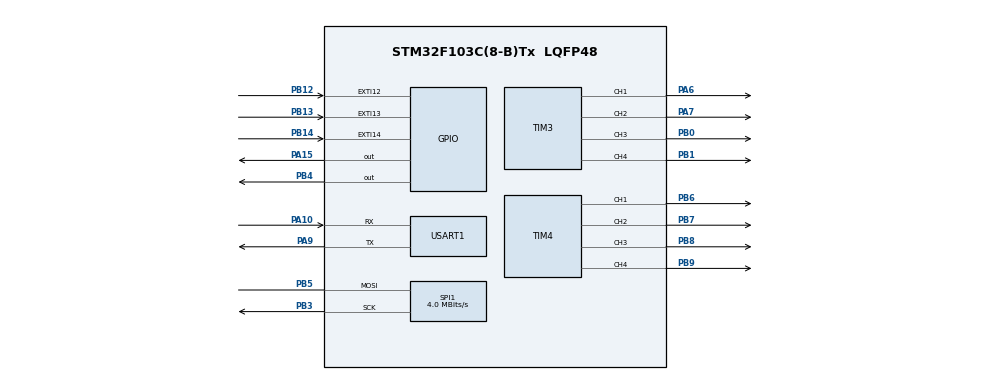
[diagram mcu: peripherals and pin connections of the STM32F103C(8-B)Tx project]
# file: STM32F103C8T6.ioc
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FREERTOS.Tasks01=defaultTask,24,128,StartDefaultTask,Default,NULL,Dynamic,NULL,NULL
Mcu.Family=STM32F1
Mcu.Name=STM32F103C(8-B)Tx
Mcu.Package=LQFP48
NVIC.PriorityGroup=NVIC_PRIORITYGROUP_4
PA10.Mode=Asynchronous
PA10.Signal=USART1_RX
PA13.Mode=Serial_Wire
PA13.Signal=SYS_JTMS-SWDIO
PA14.Mode=Serial_Wire
PA14.Signal=SYS_JTCK-SWCLK
PA15.Signal=GPIO_Output
PA6.Signal=S_TIM3_CH1
PA7.Signal=S_TIM3_CH2
PA9.Mode=Asynchronous
PA9.Signal=USART1_TX
PB0.Signal=S_TIM3_CH3
PB1.Signal=S_TIM3_CH4
PB12.GPIO_ModeDefaultEXTI=GPIO_MODE_IT_FALLING
PB12.GPIO_PuPd=GPIO_PULLUP
PB12.Signal=GPXTI12
PB13.GPIO_ModeDefaultEXTI=GPIO_MODE_IT_FALLING
PB13.GPIO_PuPd=GPIO_PULLUP
PB13.Signal=GPXTI13
PB14.GPIO_ModeDefaultEXTI=GPIO_MODE_IT_FALLING
PB14.GPIO_PuPd=GPIO_PULLUP
PB14.Signal=GPXTI14
PB3.Mode=Simplex_Bidirectional_Master
PB3.Signal=SPI1_SCK
PB4.Signal=GPIO_Output
PB5.Mode=Simplex_Bidirectional_Master
PB5.Signal=SPI1_MOSI
PB6.Signal=S_TIM4_CH1
PB7.Signal=S_TIM4_CH2
PB8.Signal=S_TIM4_CH3
PB9.Signal=S_TIM4_CH4
ProjectManager.HeapSize=0x200
ProjectManager.StackSize=0x400
ProjectManager.TargetToolchain=SW4STM32
RCC.APB1Freq_Value=8000000
RCC.APB2Freq_Value=8000000
SH.S_TIM3_CH1.0=TIM3_CH1,PWM Generation1 CH1
SH.S_TIM3_CH2.0=TIM3_CH2,PWM Generation2 CH2
SH.S_TIM3_CH3.0=TIM3_CH3,PWM Generation3 CH3
SH.S_TIM3_CH4.0=TIM3_CH4,PWM Generation4 CH4
SH.S_TIM4_CH1.0=TIM4_CH1,PWM Generation1 CH1
SH.S_TIM4_CH2.0=TIM4_CH2,PWM Generation2 CH2
SH.S_TIM4_CH3.0=TIM4_CH3,PWM Generation3 CH3
SH.S_TIM4_CH4.0=TIM4_CH4,PWM Generation4 CH4
SPI1.CalculateBaudRate=4.0 MBits/s
SPI1.Direction=SPI_DIRECTION_1LINE
SPI1.Mode=SPI_MODE_MASTER
SPI1.VirtualType=VM_MASTER
TIM3.Channel-PWM\ Generation1\ CH1=TIM_CHANNEL_1
TIM3.Channel-PWM\ Generation2\ CH2=TIM_CHANNEL_2
TIM3.Channel-PWM\ Generation3\ CH3=TIM_CHANNEL_3
TIM3.Channel-PWM\ Generation4\ CH4=TIM_CHANNEL_4
TIM4.Channel-PWM\ Generation1\ CH1=TIM_CHANNEL_1
TIM4.Channel-PWM\ Generation2\ CH2=TIM_CHANNEL_2
TIM4.Channel-PWM\ Generation3\ CH3=TIM_CHANNEL_3
TIM4.Channel-PWM\ Generation4\ CH4=TIM_CHANNEL_4
USART1.VirtualMode=VM_ASYNC
VP_FREERTOS_VS_CMSIS_V2.Mode=CMSIS_V2
board=custom

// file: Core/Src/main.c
/* USER CODE BEGIN Header */
/**
  ******************************************************************************
  * @file           : main.c
  * @brief          : Main program body
  ******************************************************************************
  * @attention
  *
  * Copyright (c) 2022 STMicroelectronics.
  * All rights reserved.
  *
  * This software is licensed under terms that can be found in the LICENSE file
  * in the root directory of this software component.
  * If no LICENSE file comes with this software, it is provided AS-IS.
  *
  ******************************************************************************
  */
/* USER CODE END Header */
#include "main.h"
#include "cmsis_os.h"
#include "tapSex.h"

 SPI_HandleTypeDef hspi1;

TIM_HandleTypeDef htim3;
TIM_HandleTypeDef htim4;

UART_HandleTypeDef huart1;

/* Definitions for defaultTask */
osThreadId_t defaultTaskHandle;
const osThreadAttr_t defaultTask_attributes = {
  .name = "defaultTask",
  .stack_size = 128 * 4,
  .priority = (osPriority_t) osPriorityNormal,
};

void SystemClock_Config(void);
static void MX_GPIO_Init(void);
static void MX_TIM4_Init(void);
static void MX_USART1_UART_Init(void);
static void MX_SPI1_Init(void);
static void MX_TIM3_Init(void);
void StartDefaultTask(void *argument);

int main(void)
{

  /* MCU Configuration--------------------------------------------------------*/

  /* Reset of all peripherals, Initializes the Flash interface and the Systick. */
  HAL_Init();

  /* Configure the system clock */
  SystemClock_Config();

  /* Initialize all configured peripherals */
  MX_GPIO_Init();
  MX_TIM4_Init();
  MX_USART1_UART_Init();
  MX_SPI1_Init();
  MX_TIM3_Init();
  /* USER CODE BEGIN 2 */
  TapSexSetHtim3(htim3);
  TapSexSetHtim4(htim4);
  /* USER CODE END 2 */

  /* Init scheduler */
  osKernelInitialize();

  /* Create the thread(s) */
  /* creation of defaultTask */
  defaultTaskHandle = osThreadNew(StartDefaultTask, NULL, &defaultTask_attributes);

  /* USER CODE BEGIN RTOS_THREADS */
  /* add threads, ... */
  TapSexTaskInit();
  /* USER CODE END RTOS_THREADS */

  /* Start scheduler */
  osKernelStart();

  /* We should never get here as control is now taken by the scheduler */
  /* Infinite loop */
  while (1)
  {

  }
}

void SystemClock_Config(void)
{
  RCC_OscInitTypeDef RCC_OscInitStruct = {0};
  RCC_ClkInitTypeDef RCC_ClkInitStruct = {0};

  /** Initializes the RCC Oscillators according to the specified parameters
  * in the RCC_OscInitTypeDef structure.
  */
  RCC_OscInitStruct.OscillatorType = RCC_OSCILLATORTYPE_HSI;
  RCC_OscInitStruct.HSIState = RCC_HSI_ON;
  RCC_OscInitStruct.HSICalibrationValue = RCC_HSICALIBRATION_DEFAULT;
  RCC_OscInitStruct.PLL.PLLState = RCC_PLL_NONE;
  if (HAL_RCC_OscConfig(&RCC_OscInitStruct) != HAL_OK)
  {
    Error_Handler();
  }

  /** Initializes the CPU, AHB and APB buses clocks
  */
  RCC_ClkInitStruct.ClockType = RCC_CLOCKTYPE_HCLK|RCC_CLOCKTYPE_SYSCLK
                              |RCC_CLOCKTYPE_PCLK1|RCC_CLOCKTYPE_PCLK2;
  RCC_ClkInitStruct.SYSCLKSource = RCC_SYSCLKSOURCE_HSI;
  RCC_ClkInitStruct.AHBCLKDivider = RCC_SYSCLK_DIV1;
  RCC_ClkInitStruct.APB1CLKDivider = RCC_HCLK_DIV1;
  RCC_ClkInitStruct.APB2CLKDivider = RCC_HCLK_DIV1;

  if (HAL_RCC_ClockConfig(&RCC_ClkInitStruct, FLASH_LATENCY_0) != HAL_OK)
  {
    Error_Handler();
  }
}

static void MX_SPI1_Init(void)
{

  /* SPI1 parameter configuration*/
  hspi1.Instance = SPI1;
  hspi1.Init.Mode = SPI_MODE_MASTER;
  hspi1.Init.Direction = SPI_DIRECTION_1LINE;
  hspi1.Init.DataSize = SPI_DATASIZE_8BIT;
  hspi1.Init.CLKPolarity = SPI_POLARITY_LOW;
  hspi1.Init.CLKPhase = SPI_PHASE_1EDGE;
  hspi1.Init.NSS = SPI_NSS_SOFT;
  hspi1.Init.BaudRatePrescaler = SPI_BAUDRATEPRESCALER_2;
  hspi1.Init.FirstBit = SPI_FIRSTBIT_MSB;
  hspi1.Init.TIMode = SPI_TIMODE_DISABLE;
  hspi1.Init.CRCCalculation = SPI_CRCCALCULATION_DISABLE;
  hspi1.Init.CRCPolynomial = 10;
  if (HAL_SPI_Init(&hspi1) != HAL_OK)
  {
    Error_Handler();
  }

}

static void MX_TIM3_Init(void)
{

  TIM_MasterConfigTypeDef sMasterConfig = {0};
  TIM_OC_InitTypeDef sConfigOC = {0};

  htim3.Instance = TIM3;
  htim3.Init.Prescaler = 0;
  htim3.Init.CounterMode = TIM_COUNTERMODE_UP;
  htim3.Init.Period = 65535;
  htim3.Init.ClockDivision = TIM_CLOCKDIVISION_DIV1;
  htim3.Init.AutoReloadPreload = TIM_AUTORELOAD_PRELOAD_DISABLE;
  if (HAL_TIM_PWM_Init(&htim3) != HAL_OK)
  {
    Error_Handler();
  }
  sMasterConfig.MasterOutputTrigger = TIM_TRGO_RESET;
  sMasterConfig.MasterSlaveMode = TIM_MASTERSLAVEMODE_DISABLE;
  if (HAL_TIMEx_MasterConfigSynchronization(&htim3, &sMasterConfig) != HAL_OK)
  {
    Error_Handler();
  }
  sConfigOC.OCMode = TIM_OCMODE_PWM1;
  sConfigOC.Pulse = 0;
  sConfigOC.OCPolarity = TIM_OCPOLARITY_HIGH;
  sConfigOC.OCFastMode = TIM_OCFAST_DISABLE;
  if (HAL_TIM_PWM_ConfigChannel(&htim3, &sConfigOC, TIM_CHANNEL_1) != HAL_OK)
  {
    Error_Handler();
  }
  if (HAL_TIM_PWM_ConfigChannel(&htim3, &sConfigOC, TIM_CHANNEL_2) != HAL_OK)
  {
    Error_Handler();
  }
  if (HAL_TIM_PWM_ConfigChannel(&htim3, &sConfigOC, TIM_CHANNEL_3) != HAL_OK)
  {
    Error_Handler();
  }
  if (HAL_TIM_PWM_ConfigChannel(&htim3, &sConfigOC, TIM_CHANNEL_4) != HAL_OK)
  {
    Error_Handler();
  }
  HAL_TIM_MspPostInit(&htim3);

}

static void MX_TIM4_Init(void)
{

  TIM_MasterConfigTypeDef sMasterConfig = {0};
  TIM_OC_InitTypeDef sConfigOC = {0};

  htim4.Instance = TIM4;
  htim4.Init.Prescaler = 0;
  htim4.Init.CounterMode = TIM_COUNTERMODE_UP;
  htim4.Init.Period = 65535;
  htim4.Init.ClockDivision = TIM_CLOCKDIVISION_DIV1;
  htim4.Init.AutoReloadPreload = TIM_AUTORELOAD_PRELOAD_DISABLE;
  if (HAL_TIM_PWM_Init(&htim4) != HAL_OK)
  {
    Error_Handler();
  }
  sMasterConfig.MasterOutputTrigger = TIM_TRGO_RESET;
  sMasterConfig.MasterSlaveMode = TIM_MASTERSLAVEMODE_DISABLE;
  if (HAL_TIMEx_MasterConfigSynchronization(&htim4, &sMasterConfig) != HAL_OK)
  {
    Error_Handler();
  }
  sConfigOC.OCMode = TIM_OCMODE_PWM1;
  sConfigOC.Pulse = 0;
  sConfigOC.OCPolarity = TIM_OCPOLARITY_HIGH;
  sConfigOC.OCFastMode = TIM_OCFAST_DISABLE;
  if (HAL_TIM_PWM_ConfigChannel(&htim4, &sConfigOC, TIM_CHANNEL_1) != HAL_OK)
  {
    Error_Handler();
  }
  if (HAL_TIM_PWM_ConfigChannel(&htim4, &sConfigOC, TIM_CHANNEL_2) != HAL_OK)
  {
    Error_Handler();
  }
  if (HAL_TIM_PWM_ConfigChannel(&htim4, &sConfigOC, TIM_CHANNEL_3) != HAL_OK)
  {
    Error_Handler();
  }
  if (HAL_TIM_PWM_ConfigChannel(&htim4, &sConfigOC, TIM_CHANNEL_4) != HAL_OK)
  {
    Error_Handler();
  }
  HAL_TIM_MspPostInit(&htim4);

}

static void MX_USART1_UART_Init(void)
{

  huart1.Instance = USART1;
  huart1.Init.BaudRate = 115200;
  huart1.Init.WordLength = UART_WORDLENGTH_8B;
  huart1.Init.StopBits = UART_STOPBITS_1;
  huart1.Init.Parity = UART_PARITY_NONE;
  huart1.Init.Mode = UART_MODE_TX_RX;
  huart1.Init.HwFlowCtl = UART_HWCONTROL_NONE;
  huart1.Init.OverSampling = UART_OVERSAMPLING_16;
  if (HAL_UART_Init(&huart1) != HAL_OK)
  {
    Error_Handler();
  }

}

static void MX_GPIO_Init(void)
{
  GPIO_InitTypeDef GPIO_InitStruct = {0};

  /* GPIO Ports Clock Enable */
  __HAL_RCC_GPIOA_CLK_ENABLE();
  __HAL_RCC_GPIOB_CLK_ENABLE();

  /*Configure GPIO pin Output Level */
  HAL_GPIO_WritePin(GPIOA, GPIO_PIN_15, GPIO_PIN_RESET);

  /*Configure GPIO pin Output Level */
  HAL_GPIO_WritePin(GPIOB, GPIO_PIN_4, GPIO_PIN_RESET);

  /*Configure GPIO pins : PB12 PB13 PB14 */
  GPIO_InitStruct.Pin = GPIO_PIN_12|GPIO_PIN_13|GPIO_PIN_14;
  GPIO_InitStruct.Mode = GPIO_MODE_IT_FALLING;
  GPIO_InitStruct.Pull = GPIO_PULLUP;
  HAL_GPIO_Init(GPIOB, &GPIO_InitStruct);

  /*Configure GPIO pin : PA15 */
  GPIO_InitStruct.Pin = GPIO_PIN_15;
  GPIO_InitStruct.Mode = GPIO_MODE_OUTPUT_PP;
  GPIO_InitStruct.Pull = GPIO_NOPULL;
  GPIO_InitStruct.Speed = GPIO_SPEED_FREQ_LOW;
  HAL_GPIO_Init(GPIOA, &GPIO_InitStruct);

  /*Configure GPIO pin : PB4 */
  GPIO_InitStruct.Pin = GPIO_PIN_4;
  GPIO_InitStruct.Mode = GPIO_MODE_OUTPUT_PP;
  GPIO_InitStruct.Pull = GPIO_NOPULL;
  GPIO_InitStruct.Speed = GPIO_SPEED_FREQ_LOW;
  HAL_GPIO_Init(GPIOB, &GPIO_InitStruct);

}

void StartDefaultTask(void *argument)
{
  for(;;)
  {
    osDelay(1);
  }
}

void Error_Handler(void)
{
  __disable_irq();
  while (1)
  {
  }
}
